[part 12 of 12: packages /ComponentTypes to /VectorAutosarExplorerGeneratedObjects/PDU_GROUP]
AUTOSAR XML (schema 4-3-0)
package /ComponentTypes  (continued)
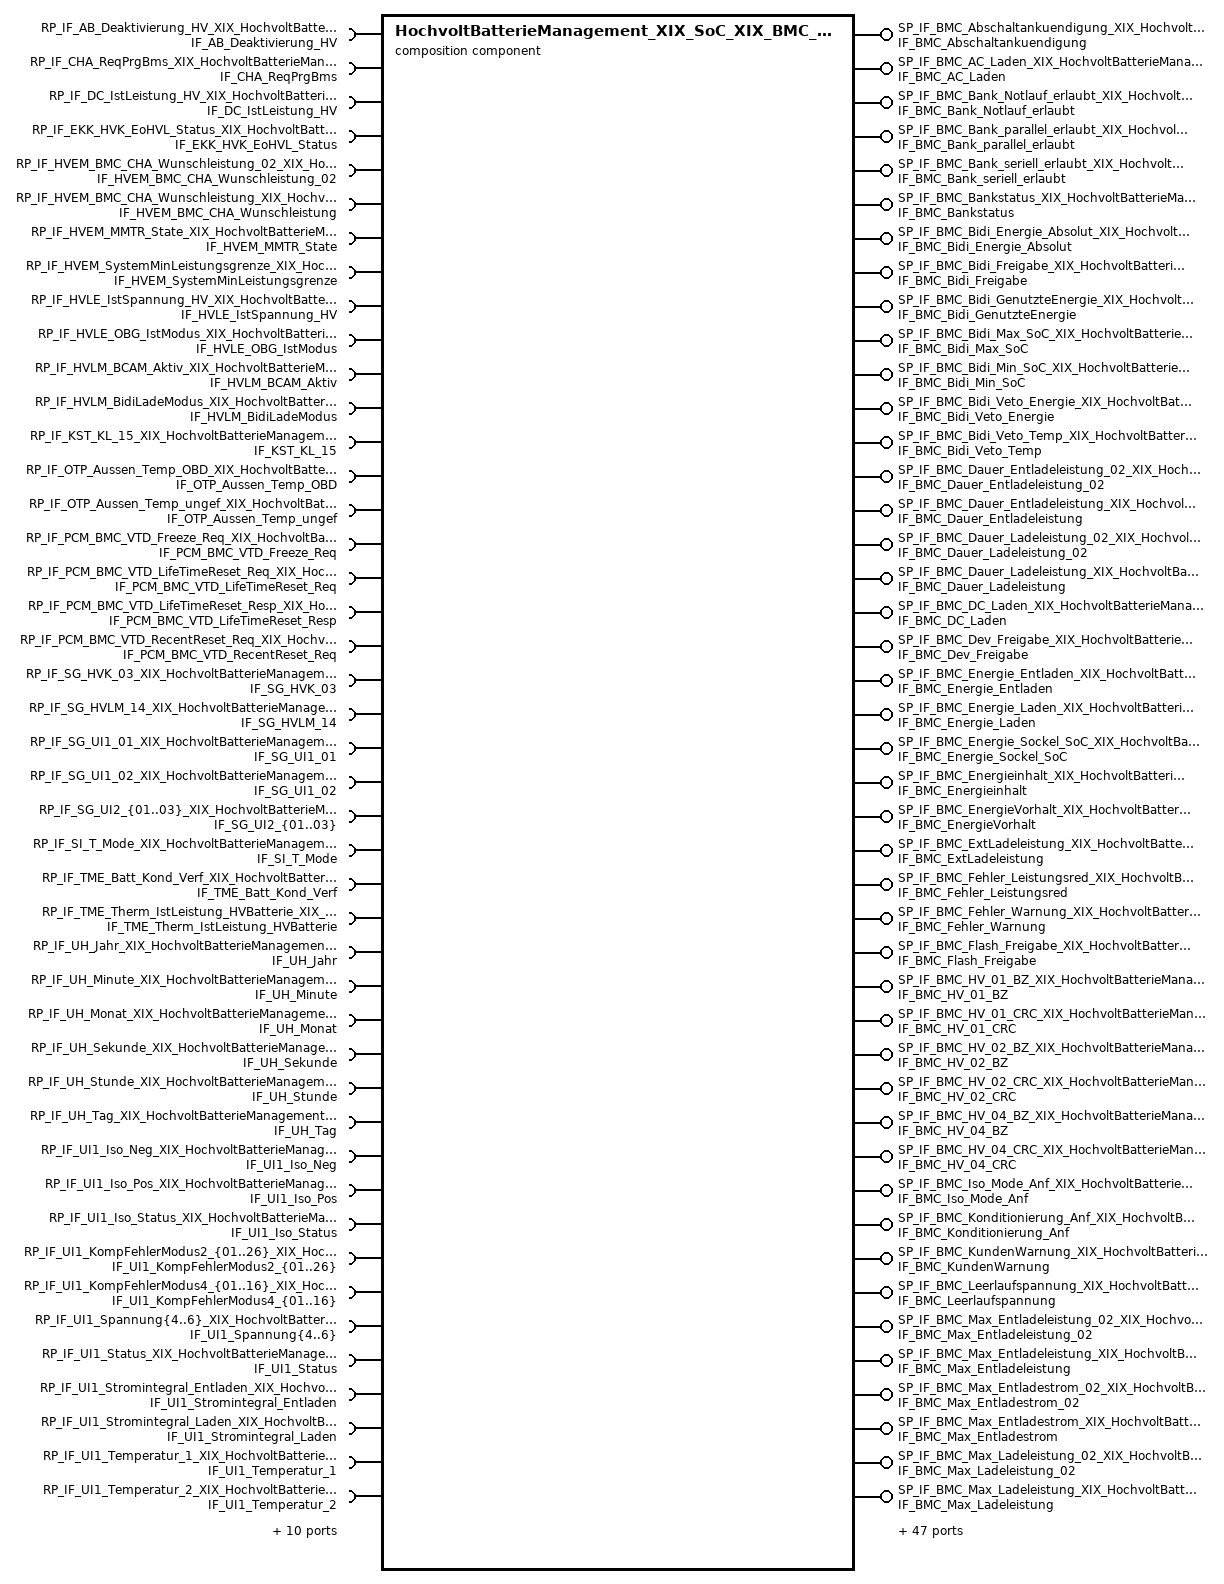
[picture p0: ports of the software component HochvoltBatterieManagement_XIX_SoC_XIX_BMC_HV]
  composition sw component type HochvoltBatterieManagement_XIX_SoC_XIX_BMC_HV
    91 x provide port:
      SP_IF_BMC_Abschaltankuendigung_XIX_HochvoltBatterieManagement_XIX_SoC_XIX_BMC_HV: provided-interface=IF_BMC_Abschaltankuendigung
      SP_IF_BMC_AC_Laden_XIX_HochvoltBatterieManagement_XIX_SoC_XIX_BMC_HV: provided-interface=IF_BMC_AC_Laden
      SP_IF_BMC_Bank_Notlauf_erlaubt_XIX_HochvoltBatterieManagement_XIX_SoC_XIX_BMC_HV: provided-interface=IF_BMC_Bank_Notlauf_erlaubt
      SP_IF_BMC_Bank_parallel_erlaubt_XIX_HochvoltBatterieManagement_XIX_SoC_XIX_BMC_HV: provided-interface=IF_BMC_Bank_parallel_erlaubt
      SP_IF_BMC_Bank_seriell_erlaubt_XIX_HochvoltBatterieManagement_XIX_SoC_XIX_BMC_HV: provided-interface=IF_BMC_Bank_seriell_erlaubt
      SP_IF_BMC_Bankstatus_XIX_HochvoltBatterieManagement_XIX_SoC_XIX_BMC_HV: provided-interface=IF_BMC_Bankstatus
      SP_IF_BMC_Bidi_Energie_Absolut_XIX_HochvoltBatterieManagement_XIX_SoC_XIX_BMC_HV: provided-interface=IF_BMC_Bidi_Energie_Absolut
      SP_IF_BMC_Bidi_Freigabe_XIX_HochvoltBatterieManagement_XIX_SoC_XIX_BMC_HV: provided-interface=IF_BMC_Bidi_Freigabe
      SP_IF_BMC_Bidi_GenutzteEnergie_XIX_HochvoltBatterieManagement_XIX_SoC_XIX_BMC_HV: provided-interface=IF_BMC_Bidi_GenutzteEnergie
      SP_IF_BMC_Bidi_Max_SoC_XIX_HochvoltBatterieManagement_XIX_SoC_XIX_BMC_HV: provided-interface=IF_BMC_Bidi_Max_SoC
      SP_IF_BMC_Bidi_Min_SoC_XIX_HochvoltBatterieManagement_XIX_SoC_XIX_BMC_HV: provided-interface=IF_BMC_Bidi_Min_SoC
      SP_IF_BMC_Bidi_Veto_Energie_XIX_HochvoltBatterieManagement_XIX_SoC_XIX_BMC_HV: provided-interface=IF_BMC_Bidi_Veto_Energie
      SP_IF_BMC_Bidi_Veto_Temp_XIX_HochvoltBatterieManagement_XIX_SoC_XIX_BMC_HV: provided-interface=IF_BMC_Bidi_Veto_Temp
      SP_IF_BMC_Dauer_Entladeleistung_02_XIX_HochvoltBatterieManagement_XIX_SoC_XIX_BMC_HV: provided-interface=IF_BMC_Dauer_Entladeleistung_02
      SP_IF_BMC_Dauer_Entladeleistung_XIX_HochvoltBatterieManagement_XIX_SoC_XIX_BMC_HV: provided-interface=IF_BMC_Dauer_Entladeleistung
      SP_IF_BMC_Dauer_Ladeleistung_02_XIX_HochvoltBatterieManagement_XIX_SoC_XIX_BMC_HV: provided-interface=IF_BMC_Dauer_Ladeleistung_02
      SP_IF_BMC_Dauer_Ladeleistung_XIX_HochvoltBatterieManagement_XIX_SoC_XIX_BMC_HV: provided-interface=IF_BMC_Dauer_Ladeleistung
      SP_IF_BMC_DC_Laden_XIX_HochvoltBatterieManagement_XIX_SoC_XIX_BMC_HV: provided-interface=IF_BMC_DC_Laden
      SP_IF_BMC_Dev_Freigabe_XIX_HochvoltBatterieManagement_XIX_SoC_XIX_BMC_HV: provided-interface=IF_BMC_Dev_Freigabe
      SP_IF_BMC_Energie_Entladen_XIX_HochvoltBatterieManagement_XIX_SoC_XIX_BMC_HV: provided-interface=IF_BMC_Energie_Entladen
      SP_IF_BMC_Energie_Laden_XIX_HochvoltBatterieManagement_XIX_SoC_XIX_BMC_HV: provided-interface=IF_BMC_Energie_Laden
      SP_IF_BMC_Energie_Sockel_SoC_XIX_HochvoltBatterieManagement_XIX_SoC_XIX_BMC_HV: provided-interface=IF_BMC_Energie_Sockel_SoC
      SP_IF_BMC_Energieinhalt_XIX_HochvoltBatterieManagement_XIX_SoC_XIX_BMC_HV: provided-interface=IF_BMC_Energieinhalt
      SP_IF_BMC_EnergieVorhalt_XIX_HochvoltBatterieManagement_XIX_SoC_XIX_BMC_HV: provided-interface=IF_BMC_EnergieVorhalt
      SP_IF_BMC_ExtLadeleistung_XIX_HochvoltBatterieManagement_XIX_SoC_XIX_BMC_HV: provided-interface=IF_BMC_ExtLadeleistung
      SP_IF_BMC_Fehler_Leistungsred_XIX_HochvoltBatterieManagement_XIX_SoC_XIX_BMC_HV: provided-interface=IF_BMC_Fehler_Leistungsred
      SP_IF_BMC_Fehler_Warnung_XIX_HochvoltBatterieManagement_XIX_SoC_XIX_BMC_HV: provided-interface=IF_BMC_Fehler_Warnung
      SP_IF_BMC_Flash_Freigabe_XIX_HochvoltBatterieManagement_XIX_SoC_XIX_BMC_HV: provided-interface=IF_BMC_Flash_Freigabe
      SP_IF_BMC_HV_01_BZ_XIX_HochvoltBatterieManagement_XIX_SoC_XIX_BMC_HV: provided-interface=IF_BMC_HV_01_BZ
      SP_IF_BMC_HV_01_CRC_XIX_HochvoltBatterieManagement_XIX_SoC_XIX_BMC_HV: provided-interface=IF_BMC_HV_01_CRC
      SP_IF_BMC_HV_02_BZ_XIX_HochvoltBatterieManagement_XIX_SoC_XIX_BMC_HV: provided-interface=IF_BMC_HV_02_BZ
      SP_IF_BMC_HV_02_CRC_XIX_HochvoltBatterieManagement_XIX_SoC_XIX_BMC_HV: provided-interface=IF_BMC_HV_02_CRC
      SP_IF_BMC_HV_04_BZ_XIX_HochvoltBatterieManagement_XIX_SoC_XIX_BMC_HV: provided-interface=IF_BMC_HV_04_BZ
      SP_IF_BMC_HV_04_CRC_XIX_HochvoltBatterieManagement_XIX_SoC_XIX_BMC_HV: provided-interface=IF_BMC_HV_04_CRC
      SP_IF_BMC_Iso_Mode_Anf_XIX_HochvoltBatterieManagement_XIX_SoC_XIX_BMC_HV: provided-interface=IF_BMC_Iso_Mode_Anf
      SP_IF_BMC_Konditionierung_Anf_XIX_HochvoltBatterieManagement_XIX_SoC_XIX_BMC_HV: provided-interface=IF_BMC_Konditionierung_Anf
      SP_IF_BMC_KundenWarnung_XIX_HochvoltBatterieManagement_XIX_SoC_XIX_BMC_HV: provided-interface=IF_BMC_KundenWarnung
      SP_IF_BMC_Leerlaufspannung_XIX_HochvoltBatterieManagement_XIX_SoC_XIX_BMC_HV: provided-interface=IF_BMC_Leerlaufspannung
      SP_IF_BMC_Max_Entladeleistung_02_XIX_HochvoltBatterieManagement_XIX_SoC_XIX_BMC_HV: provided-interface=IF_BMC_Max_Entladeleistung_02
      SP_IF_BMC_Max_Entladeleistung_XIX_HochvoltBatterieManagement_XIX_SoC_XIX_BMC_HV: provided-interface=IF_BMC_Max_Entladeleistung
      SP_IF_BMC_Max_Entladestrom_02_XIX_HochvoltBatterieManagement_XIX_SoC_XIX_BMC_HV: provided-interface=IF_BMC_Max_Entladestrom_02
      SP_IF_BMC_Max_Entladestrom_XIX_HochvoltBatterieManagement_XIX_SoC_XIX_BMC_HV: provided-interface=IF_BMC_Max_Entladestrom
      SP_IF_BMC_Max_Ladeleistung_02_XIX_HochvoltBatterieManagement_XIX_SoC_XIX_BMC_HV: provided-interface=IF_BMC_Max_Ladeleistung_02
      SP_IF_BMC_Max_Ladeleistung_XIX_HochvoltBatterieManagement_XIX_SoC_XIX_BMC_HV: provided-interface=IF_BMC_Max_Ladeleistung
      SP_IF_BMC_Max_Ladestrom_02_XIX_HochvoltBatterieManagement_XIX_SoC_XIX_BMC_HV: provided-interface=IF_BMC_Max_Ladestrom_02
      SP_IF_BMC_Max_Ladestrom_XIX_HochvoltBatterieManagement_XIX_SoC_XIX_BMC_HV: provided-interface=IF_BMC_Max_Ladestrom
      SP_IF_BMC_Max_Spannung_XIX_HochvoltBatterieManagement_XIX_SoC_XIX_BMC_HV: provided-interface=IF_BMC_Max_Spannung
      SP_IF_BMC_MaxEnergieinhalt_XIX_HochvoltBatterieManagement_XIX_SoC_XIX_BMC_HV: provided-interface=IF_BMC_MaxEnergieinhalt
      SP_IF_BMC_Min_Spannung_XIX_HochvoltBatterieManagement_XIX_SoC_XIX_BMC_HV: provided-interface=IF_BMC_Min_Spannung
      SP_IF_BMC_MinDyn_Entladespannung_XIX_HochvoltBatterieManagement_XIX_SoC_XIX_BMC_HV: provided-interface=IF_BMC_MinDyn_Entladespannung
      SP_IF_BMC_MinDyn_Ladespannung_XIX_HochvoltBatterieManagement_XIX_SoC_XIX_BMC_HV: provided-interface=IF_BMC_MinDyn_Ladespannung
      SP_IF_BMC_MMTR_Status_XIX_HochvoltBatterieManagement_XIX_SoC_XIX_BMC_HV: provided-interface=IF_BMC_MMTR_Status
      SP_IF_BMC_NutzbareKapazitaet_XIX_HochvoltBatterieManagement_XIX_SoC_XIX_BMC_HV: provided-interface=IF_BMC_NutzbareKapazitaet
      SP_IF_BMC_NutzbarerSOC_XIX_HochvoltBatterieManagement_XIX_SoC_XIX_BMC_HV: provided-interface=IF_BMC_NutzbarerSOC
      SP_IF_BMC_PCM_VTD_Freeze_Req_XIX_HochvoltBatterieManagement_XIX_SoC_XIX_BMC_HV: provided-interface=IF_BMC_PCM_VTD_Freeze_Req
      SP_IF_BMC_PCM_VTD_LifeTimeReset_Req_XIX_HochvoltBatterieManagement_XIX_SoC_XIX_BMC_HV: provided-interface=IF_BMC_PCM_VTD_LifeTimeReset_Req
      SP_IF_BMC_PCM_VTD_LifeTimeReset_Resp_XIX_HochvoltBatterieManagement_XIX_SoC_XIX_BMC_HV: provided-interface=IF_BMC_PCM_VTD_LifeTimeReset_Resp
      SP_IF_BMC_PCM_VTD_RecentReset_Req_XIX_HochvoltBatterieManagement_XIX_SoC_XIX_BMC_HV: provided-interface=IF_BMC_PCM_VTD_RecentReset_Req
      SP_IF_BMC_PerfInd_Entladen_XIX_HochvoltBatterieManagement_XIX_SoC_XIX_BMC_HV: provided-interface=IF_BMC_PerfInd_Entladen
      SP_IF_BMC_PerfInd_Laden_XIX_HochvoltBatterieManagement_XIX_SoC_XIX_BMC_HV: provided-interface=IF_BMC_PerfInd_Laden
      SP_IF_BMC_PredLeistung_StuetzungNV_XIX_HochvoltBatterieManagement_XIX_SoC_XIX_BMC_HV: provided-interface=IF_BMC_PredLeistung_StuetzungNV
      SP_IF_BMC_Range_Indikator_XIX_HochvoltBatterieManagement_XIX_SoC_XIX_BMC_HV: provided-interface=IF_BMC_Range_Indikator
      SP_IF_BMC_Rekuperation_Ueberlauf_XIX_HochvoltBatterieManagement_XIX_SoC_XIX_BMC_HV: provided-interface=IF_BMC_Rekuperation_Ueberlauf
      SP_IF_BMC_Rekuperation_XIX_HochvoltBatterieManagement_XIX_SoC_XIX_BMC_HV: provided-interface=IF_BMC_Rekuperation
      SP_IF_BMC_RuecklaufTemperatur_XIX_HochvoltBatterieManagement_XIX_SoC_XIX_BMC_HV: provided-interface=IF_BMC_RuecklaufTemperatur
      SP_IF_BMC_Spannung_DC_Ladesaeule_XIX_HochvoltBatterieManagement_XIX_SoC_XIX_BMC_HV: provided-interface=IF_BMC_Spannung_DC_Ladesaeule
      SP_IF_BMC_Spannung_XIX_HochvoltBatterieManagement_XIX_SoC_XIX_BMC_HV: provided-interface=IF_BMC_Spannung
      SP_IF_BMC_Spannung_ZwischenKreis_2_XIX_HochvoltBatterieManagement_XIX_SoC_XIX_BMC_HV: provided-interface=IF_BMC_Spannung_ZwischenKreis_2
      SP_IF_BMC_Spannung_ZwischenKreis_XIX_HochvoltBatterieManagement_XIX_SoC_XIX_BMC_HV: provided-interface=IF_BMC_Spannung_ZwischenKreis
      SP_IF_BMC_Status_DCLS_XIX_HochvoltBatterieManagement_XIX_SoC_XIX_BMC_HV: provided-interface=IF_BMC_Status_DCLS
      SP_IF_BMC_Strom_02_XIX_HochvoltBatterieManagement_XIX_SoC_XIX_BMC_HV: provided-interface=IF_BMC_Strom_02
      SP_IF_BMC_Strom_XIX_HochvoltBatterieManagement_XIX_SoC_XIX_BMC_HV: provided-interface=IF_BMC_Strom
      SP_IF_BMC_TechnischerSOC_XIX_HochvoltBatterieManagement_XIX_SoC_XIX_BMC_HV: provided-interface=IF_BMC_TechnischerSOC
      SP_IF_BMC_Temperatur_XIX_HochvoltBatterieManagement_XIX_SoC_XIX_BMC_HV: provided-interface=IF_BMC_Temperatur
      SP_IF_BMC_ThermAuslastung_XIX_HochvoltBatterieManagement_XIX_SoC_XIX_BMC_HV: provided-interface=IF_BMC_ThermAuslastung
      SP_IF_BMC_ThermSpreizung_XIX_HochvoltBatterieManagement_XIX_SoC_XIX_BMC_HV: provided-interface=IF_BMC_ThermSpreizung
      SP_IF_BMC_UBE_Indik_last_update_km_XIX_HochvoltBatterieManagement_XIX_SoC_XIX_BMC_HV: provided-interface=IF_BMC_UBE_Indik_last_update_km
      SP_IF_BMC_UBE_Indikator_XIX_HochvoltBatterieManagement_XIX_SoC_XIX_BMC_HV: provided-interface=IF_BMC_UBE_Indikator
      SP_IF_BMC_UI1_Spannung1_Schalt_Anf_XIX_HochvoltBatterieManagement_XIX_SoC_XIX_BMC_HV: provided-interface=IF_BMC_UI1_Spannung1_Schalt_Anf
      SP_IF_BMC_UI1_Spannung2_Schalt_Anf_XIX_HochvoltBatterieManagement_XIX_SoC_XIX_BMC_HV: provided-interface=IF_BMC_UI1_Spannung2_Schalt_Anf
      SP_IF_BMC_UI2_Spannung1_Schalt_Anf_XIX_HochvoltBatterieManagement_XIX_SoC_XIX_BMC_HV: provided-interface=IF_BMC_UI2_Spannung1_Schalt_Anf
      SP_IF_BMC_UI2_Spannung2_Schalt_Anf_XIX_HochvoltBatterieManagement_XIX_SoC_XIX_BMC_HV: provided-interface=IF_BMC_UI2_Spannung2_Schalt_Anf
      SP_IF_BMC_Unterboden_Warnung_XIX_HochvoltBatterieManagement_XIX_SoC_XIX_BMC_HV: provided-interface=IF_BMC_Unterboden_Warnung
      SP_IF_BMC_Verbauinfo_ACSchuetz_XIX_HochvoltBatterieManagement_XIX_SoC_XIX_BMC_HV: provided-interface=IF_BMC_Verbauinfo_ACSchuetz
      SP_IF_BMC_Verbauinfo_Bank_XIX_HochvoltBatterieManagement_XIX_SoC_XIX_BMC_HV: provided-interface=IF_BMC_Verbauinfo_Bank
      SP_IF_BMC_Verbrauch_Ueberlauf_XIX_HochvoltBatterieManagement_XIX_SoC_XIX_BMC_HV: provided-interface=IF_BMC_Verbrauch_Ueberlauf
      SP_IF_BMC_Verbrauch_XIX_HochvoltBatterieManagement_XIX_SoC_XIX_BMC_HV: provided-interface=IF_BMC_Verbrauch
      SP_IF_BMC_VerlustEnergie_XIX_HochvoltBatterieManagement_XIX_SoC_XIX_BMC_HV: provided-interface=IF_BMC_VerlustEnergie
      SP_IF_BMC_VorlaufTemperatur_XIX_HochvoltBatterieManagement_XIX_SoC_XIX_BMC_HV: provided-interface=IF_BMC_VorlaufTemperatur
      SP_IF_BMC_ZellTemp_virtuell_max_XIX_HochvoltBatterieManagement_XIX_SoC_XIX_BMC_HV: provided-interface=IF_BMC_ZellTemp_virtuell_max
      SP_IF_BMC_ZellTemp_virtuell_min_XIX_HochvoltBatterieManagement_XIX_SoC_XIX_BMC_HV: provided-interface=IF_BMC_ZellTemp_virtuell_min
    138 x require port:
      RP_IF_AB_Deaktivierung_HV_XIX_HochvoltBatterieManagement_XIX_SoC_XIX_BMC_HV: required-interface=IF_AB_Deaktivierung_HV
      RP_IF_CHA_ReqPrgBms_XIX_HochvoltBatterieManagement_XIX_SoC_XIX_BMC_HV: required-interface=IF_CHA_ReqPrgBms
      RP_IF_DC_IstLeistung_HV_XIX_HochvoltBatterieManagement_XIX_SoC_XIX_BMC_HV: required-interface=IF_DC_IstLeistung_HV
      RP_IF_EKK_HVK_EoHVL_Status_XIX_HochvoltBatterieManagement_XIX_SoC_XIX_BMC_HV: required-interface=IF_EKK_HVK_EoHVL_Status
      RP_IF_HVEM_BMC_CHA_Wunschleistung_02_XIX_HochvoltBatterieManagement_XIX_SoC_XIX_BMC_HV: required-interface=IF_HVEM_BMC_CHA_Wunschleistung_02
      RP_IF_HVEM_BMC_CHA_Wunschleistung_XIX_HochvoltBatterieManagement_XIX_SoC_XIX_BMC_HV: required-interface=IF_HVEM_BMC_CHA_Wunschleistung
      RP_IF_HVEM_MMTR_State_XIX_HochvoltBatterieManagement_XIX_SoC_XIX_BMC_HV: required-interface=IF_HVEM_MMTR_State
      RP_IF_HVEM_SystemMinLeistungsgrenze_XIX_HochvoltBatterieManagement_XIX_SoC_XIX_BMC_HV: required-interface=IF_HVEM_SystemMinLeistungsgrenze
      RP_IF_HVLE_IstSpannung_HV_XIX_HochvoltBatterieManagement_XIX_SoC_XIX_BMC_HV: required-interface=IF_HVLE_IstSpannung_HV
      RP_IF_HVLE_OBG_IstModus_XIX_HochvoltBatterieManagement_XIX_SoC_XIX_BMC_HV: required-interface=IF_HVLE_OBG_IstModus
      RP_IF_HVLM_BCAM_Aktiv_XIX_HochvoltBatterieManagement_XIX_SoC_XIX_BMC_HV: required-interface=IF_HVLM_BCAM_Aktiv
      RP_IF_HVLM_BidiLadeModus_XIX_HochvoltBatterieManagement_XIX_SoC_XIX_BMC_HV: required-interface=IF_HVLM_BidiLadeModus
      RP_IF_KST_KL_15_XIX_HochvoltBatterieManagement_XIX_SoC_XIX_BMC_HV: required-interface=IF_KST_KL_15
      RP_IF_OTP_Aussen_Temp_OBD_XIX_HochvoltBatterieManagement_XIX_SoC_XIX_BMC_HV: required-interface=IF_OTP_Aussen_Temp_OBD
      RP_IF_OTP_Aussen_Temp_ungef_XIX_HochvoltBatterieManagement_XIX_SoC_XIX_BMC_HV: required-interface=IF_OTP_Aussen_Temp_ungef
      RP_IF_PCM_BMC_VTD_Freeze_Req_XIX_HochvoltBatterieManagement_XIX_SoC_XIX_BMC_HV: required-interface=IF_PCM_BMC_VTD_Freeze_Req
      RP_IF_PCM_BMC_VTD_LifeTimeReset_Req_XIX_HochvoltBatterieManagement_XIX_SoC_XIX_BMC_HV: required-interface=IF_PCM_BMC_VTD_LifeTimeReset_Req
      RP_IF_PCM_BMC_VTD_LifeTimeReset_Resp_XIX_HochvoltBatterieManagement_XIX_SoC_XIX_BMC_HV: required-interface=IF_PCM_BMC_VTD_LifeTimeReset_Resp
      RP_IF_PCM_BMC_VTD_RecentReset_Req_XIX_HochvoltBatterieManagement_XIX_SoC_XIX_BMC_HV: required-interface=IF_PCM_BMC_VTD_RecentReset_Req
      RP_IF_SG_HVK_03_XIX_HochvoltBatterieManagement_XIX_SoC_XIX_BMC_HV: required-interface=IF_SG_HVK_03
      RP_IF_SG_HVLM_14_XIX_HochvoltBatterieManagement_XIX_SoC_XIX_BMC_HV: required-interface=IF_SG_HVLM_14
      RP_IF_SG_UI1_01_XIX_HochvoltBatterieManagement_XIX_SoC_XIX_BMC_HV: required-interface=IF_SG_UI1_01
      RP_IF_SG_UI1_02_XIX_HochvoltBatterieManagement_XIX_SoC_XIX_BMC_HV: required-interface=IF_SG_UI1_02
      RP_IF_SG_UI2_{01..03}_XIX_HochvoltBatterieManagement_XIX_SoC_XIX_BMC_HV: required-interface=IF_SG_UI2_{01..03}
      RP_IF_SI_T_Mode_XIX_HochvoltBatterieManagement_XIX_SoC_XIX_BMC_HV: required-interface=IF_SI_T_Mode
      RP_IF_TME_Batt_Kond_Verf_XIX_HochvoltBatterieManagement_XIX_SoC_XIX_BMC_HV: required-interface=IF_TME_Batt_Kond_Verf
      RP_IF_TME_Therm_IstLeistung_HVBatterie_XIX_HochvoltBatterieManagement_XIX_SoC_XIX_BMC_HV: required-interface=IF_TME_Therm_IstLeistung_HVBatterie
      RP_IF_UH_Jahr_XIX_HochvoltBatterieManagement_XIX_SoC_XIX_BMC_HV: required-interface=IF_UH_Jahr
      RP_IF_UH_Minute_XIX_HochvoltBatterieManagement_XIX_SoC_XIX_BMC_HV: required-interface=IF_UH_Minute
      RP_IF_UH_Monat_XIX_HochvoltBatterieManagement_XIX_SoC_XIX_BMC_HV: required-interface=IF_UH_Monat
      RP_IF_UH_Sekunde_XIX_HochvoltBatterieManagement_XIX_SoC_XIX_BMC_HV: required-interface=IF_UH_Sekunde
      RP_IF_UH_Stunde_XIX_HochvoltBatterieManagement_XIX_SoC_XIX_BMC_HV: required-interface=IF_UH_Stunde
      RP_IF_UH_Tag_XIX_HochvoltBatterieManagement_XIX_SoC_XIX_BMC_HV: required-interface=IF_UH_Tag
      RP_IF_UI1_Iso_Neg_XIX_HochvoltBatterieManagement_XIX_SoC_XIX_BMC_HV: required-interface=IF_UI1_Iso_Neg
      RP_IF_UI1_Iso_Pos_XIX_HochvoltBatterieManagement_XIX_SoC_XIX_BMC_HV: required-interface=IF_UI1_Iso_Pos
      RP_IF_UI1_Iso_Status_XIX_HochvoltBatterieManagement_XIX_SoC_XIX_BMC_HV: required-interface=IF_UI1_Iso_Status
      RP_IF_UI1_KompFehlerModus2_{01..26}_XIX_HochvoltBatterieManagement_XIX_SoC_XIX_BMC_HV: required-interface=IF_UI1_KompFehlerModus2_{01..26}
      RP_IF_UI1_KompFehlerModus4_{01..16}_XIX_HochvoltBatterieManagement_XIX_SoC_XIX_BMC_HV: required-interface=IF_UI1_KompFehlerModus4_{01..16}
      RP_IF_UI1_Spannung{4..6}_XIX_HochvoltBatterieManagement_XIX_SoC_XIX_BMC_HV: required-interface=IF_UI1_Spannung{4..6}
      RP_IF_UI1_Status_XIX_HochvoltBatterieManagement_XIX_SoC_XIX_BMC_HV: required-interface=IF_UI1_Status
      RP_IF_UI1_Stromintegral_Entladen_XIX_HochvoltBatterieManagement_XIX_SoC_XIX_BMC_HV: required-interface=IF_UI1_Stromintegral_Entladen
      RP_IF_UI1_Stromintegral_Laden_XIX_HochvoltBatterieManagement_XIX_SoC_XIX_BMC_HV: required-interface=IF_UI1_Stromintegral_Laden
      RP_IF_UI1_Temperatur_1_XIX_HochvoltBatterieManagement_XIX_SoC_XIX_BMC_HV: required-interface=IF_UI1_Temperatur_1
      RP_IF_UI1_Temperatur_2_XIX_HochvoltBatterieManagement_XIX_SoC_XIX_BMC_HV: required-interface=IF_UI1_Temperatur_2
      RP_IF_UI2_KompFehlerModus2_{01..26}_XIX_HochvoltBatterieManagement_XIX_SoC_XIX_BMC_HV: required-interface=IF_UI2_KompFehlerModus2_{01..26}
      RP_IF_UI2_KompFehlerModus4_{01..16}_XIX_HochvoltBatterieManagement_XIX_SoC_XIX_BMC_HV: required-interface=IF_UI2_KompFehlerModus4_{01..16}
      RP_IF_UI2_Status_XIX_HochvoltBatterieManagement_XIX_SoC_XIX_BMC_HV: required-interface=IF_UI2_Status
      RP_IF_UI2_Stromintegral_Entladen_XIX_HochvoltBatterieManagement_XIX_SoC_XIX_BMC_HV: required-interface=IF_UI2_Stromintegral_Entladen
      RP_IF_UI2_Stromintegral_Laden_XIX_HochvoltBatterieManagement_XIX_SoC_XIX_BMC_HV: required-interface=IF_UI2_Stromintegral_Laden
      RP_IF_UI2_Temperatur_1_XIX_HochvoltBatterieManagement_XIX_SoC_XIX_BMC_HV: required-interface=IF_UI2_Temperatur_1
      RP_IF_UI2_Temperatur_2_XIX_HochvoltBatterieManagement_XIX_SoC_XIX_BMC_HV: required-interface=IF_UI2_Temperatur_2
      RP_IF_ZM_HV_Auszeit_HiRes_XIX_HochvoltBatterieManagement_XIX_SoC_XIX_BMC_HV: required-interface=IF_ZM_HV_Auszeit_HiRes
      RP_IF_ZM_HV_Auszeit_Status_XIX_HochvoltBatterieManagement_XIX_SoC_XIX_BMC_HV: required-interface=IF_ZM_HV_Auszeit_Status
      RP_IF_ZM_HV_Auszeit_XIX_HochvoltBatterieManagement_XIX_SoC_XIX_BMC_HV: required-interface=IF_ZM_HV_Auszeit
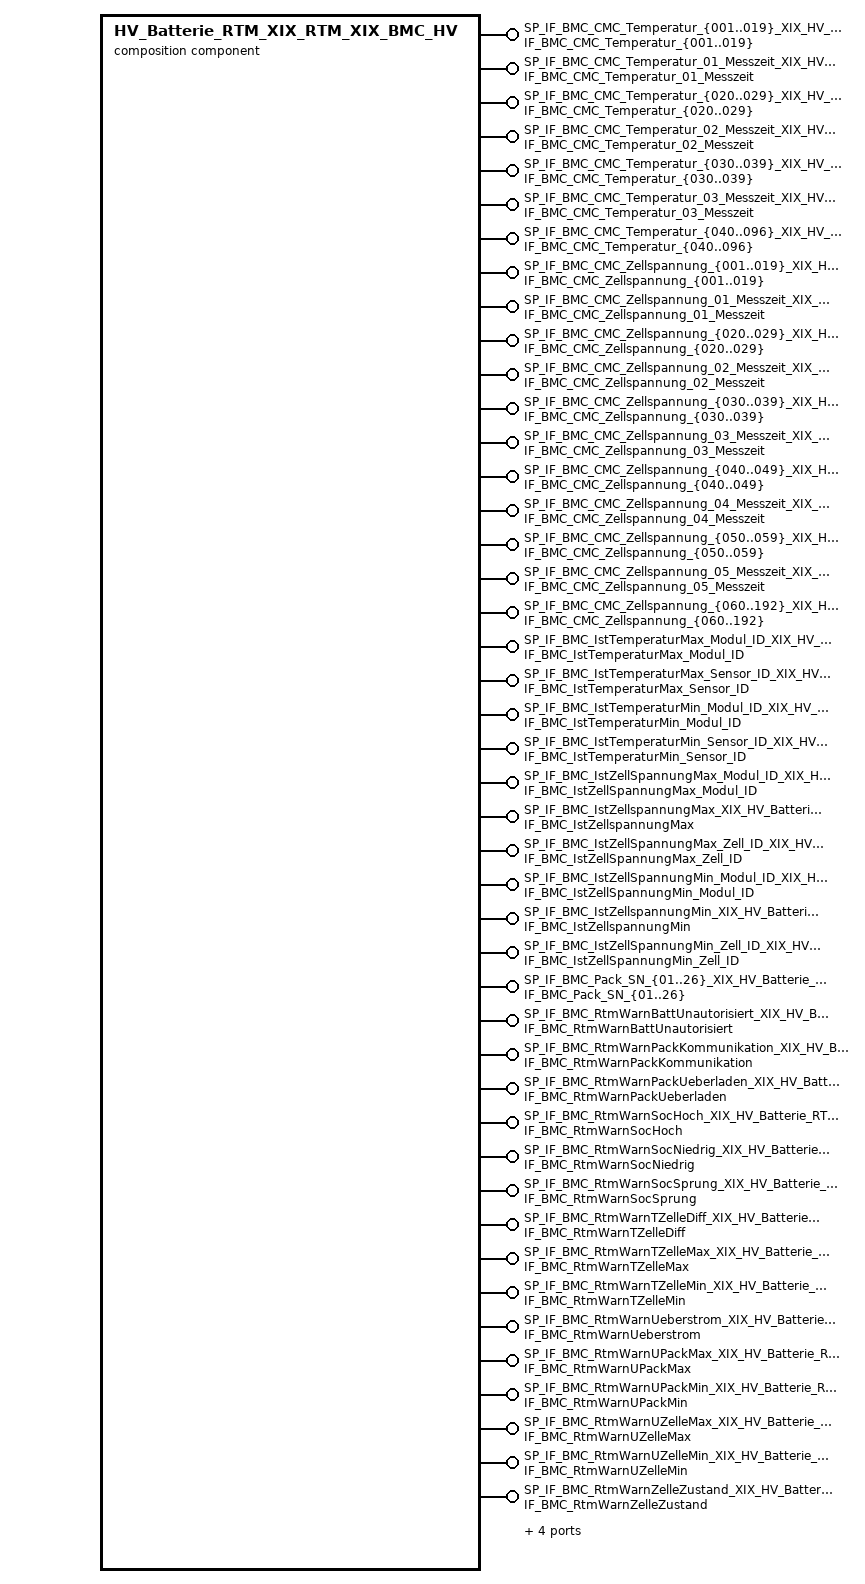
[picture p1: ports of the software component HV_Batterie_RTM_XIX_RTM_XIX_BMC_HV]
  composition sw component type HV_Batterie_RTM_XIX_RTM_XIX_BMC_HV
    351 x provide port:
      SP_IF_BMC_CMC_Temperatur_{001..019}_XIX_HV_Batterie_RTM_XIX_RTM_XIX_BMC_HV: provided-interface=IF_BMC_CMC_Temperatur_{001..019}
      SP_IF_BMC_CMC_Temperatur_01_Messzeit_XIX_HV_Batterie_RTM_XIX_RTM_XIX_BMC_HV: provided-interface=IF_BMC_CMC_Temperatur_01_Messzeit
      SP_IF_BMC_CMC_Temperatur_{020..029}_XIX_HV_Batterie_RTM_XIX_RTM_XIX_BMC_HV: provided-interface=IF_BMC_CMC_Temperatur_{020..029}
      SP_IF_BMC_CMC_Temperatur_02_Messzeit_XIX_HV_Batterie_RTM_XIX_RTM_XIX_BMC_HV: provided-interface=IF_BMC_CMC_Temperatur_02_Messzeit
      SP_IF_BMC_CMC_Temperatur_{030..039}_XIX_HV_Batterie_RTM_XIX_RTM_XIX_BMC_HV: provided-interface=IF_BMC_CMC_Temperatur_{030..039}
      SP_IF_BMC_CMC_Temperatur_03_Messzeit_XIX_HV_Batterie_RTM_XIX_RTM_XIX_BMC_HV: provided-interface=IF_BMC_CMC_Temperatur_03_Messzeit
      SP_IF_BMC_CMC_Temperatur_{040..096}_XIX_HV_Batterie_RTM_XIX_RTM_XIX_BMC_HV: provided-interface=IF_BMC_CMC_Temperatur_{040..096}
      SP_IF_BMC_CMC_Zellspannung_{001..019}_XIX_HV_Batterie_RTM_XIX_RTM_XIX_BMC_HV: provided-interface=IF_BMC_CMC_Zellspannung_{001..019}
      SP_IF_BMC_CMC_Zellspannung_01_Messzeit_XIX_HV_Batterie_RTM_XIX_RTM_XIX_BMC_HV: provided-interface=IF_BMC_CMC_Zellspannung_01_Messzeit
      SP_IF_BMC_CMC_Zellspannung_{020..029}_XIX_HV_Batterie_RTM_XIX_RTM_XIX_BMC_HV: provided-interface=IF_BMC_CMC_Zellspannung_{020..029}
      SP_IF_BMC_CMC_Zellspannung_02_Messzeit_XIX_HV_Batterie_RTM_XIX_RTM_XIX_BMC_HV: provided-interface=IF_BMC_CMC_Zellspannung_02_Messzeit
      SP_IF_BMC_CMC_Zellspannung_{030..039}_XIX_HV_Batterie_RTM_XIX_RTM_XIX_BMC_HV: provided-interface=IF_BMC_CMC_Zellspannung_{030..039}
      SP_IF_BMC_CMC_Zellspannung_03_Messzeit_XIX_HV_Batterie_RTM_XIX_RTM_XIX_BMC_HV: provided-interface=IF_BMC_CMC_Zellspannung_03_Messzeit
      SP_IF_BMC_CMC_Zellspannung_{040..049}_XIX_HV_Batterie_RTM_XIX_RTM_XIX_BMC_HV: provided-interface=IF_BMC_CMC_Zellspannung_{040..049}
      SP_IF_BMC_CMC_Zellspannung_04_Messzeit_XIX_HV_Batterie_RTM_XIX_RTM_XIX_BMC_HV: provided-interface=IF_BMC_CMC_Zellspannung_04_Messzeit
      SP_IF_BMC_CMC_Zellspannung_{050..059}_XIX_HV_Batterie_RTM_XIX_RTM_XIX_BMC_HV: provided-interface=IF_BMC_CMC_Zellspannung_{050..059}
      SP_IF_BMC_CMC_Zellspannung_05_Messzeit_XIX_HV_Batterie_RTM_XIX_RTM_XIX_BMC_HV: provided-interface=IF_BMC_CMC_Zellspannung_05_Messzeit
      SP_IF_BMC_CMC_Zellspannung_{060..192}_XIX_HV_Batterie_RTM_XIX_RTM_XIX_BMC_HV: provided-interface=IF_BMC_CMC_Zellspannung_{060..192}
      SP_IF_BMC_IstTemperaturMax_Modul_ID_XIX_HV_Batterie_RTM_XIX_RTM_XIX_BMC_HV: provided-interface=IF_BMC_IstTemperaturMax_Modul_ID
      SP_IF_BMC_IstTemperaturMax_Sensor_ID_XIX_HV_Batterie_RTM_XIX_RTM_XIX_BMC_HV: provided-interface=IF_BMC_IstTemperaturMax_Sensor_ID
      SP_IF_BMC_IstTemperaturMin_Modul_ID_XIX_HV_Batterie_RTM_XIX_RTM_XIX_BMC_HV: provided-interface=IF_BMC_IstTemperaturMin_Modul_ID
      SP_IF_BMC_IstTemperaturMin_Sensor_ID_XIX_HV_Batterie_RTM_XIX_RTM_XIX_BMC_HV: provided-interface=IF_BMC_IstTemperaturMin_Sensor_ID
      SP_IF_BMC_IstZellSpannungMax_Modul_ID_XIX_HV_Batterie_RTM_XIX_RTM_XIX_BMC_HV: provided-interface=IF_BMC_IstZellSpannungMax_Modul_ID
      SP_IF_BMC_IstZellspannungMax_XIX_HV_Batterie_RTM_XIX_RTM_XIX_BMC_HV: provided-interface=IF_BMC_IstZellspannungMax
      SP_IF_BMC_IstZellSpannungMax_Zell_ID_XIX_HV_Batterie_RTM_XIX_RTM_XIX_BMC_HV: provided-interface=IF_BMC_IstZellSpannungMax_Zell_ID
      SP_IF_BMC_IstZellSpannungMin_Modul_ID_XIX_HV_Batterie_RTM_XIX_RTM_XIX_BMC_HV: provided-interface=IF_BMC_IstZellSpannungMin_Modul_ID
      SP_IF_BMC_IstZellspannungMin_XIX_HV_Batterie_RTM_XIX_RTM_XIX_BMC_HV: provided-interface=IF_BMC_IstZellspannungMin
      SP_IF_BMC_IstZellSpannungMin_Zell_ID_XIX_HV_Batterie_RTM_XIX_RTM_XIX_BMC_HV: provided-interface=IF_BMC_IstZellSpannungMin_Zell_ID
      SP_IF_BMC_Pack_SN_{01..26}_XIX_HV_Batterie_RTM_XIX_RTM_XIX_BMC_HV: provided-interface=IF_BMC_Pack_SN_{01..26}
      SP_IF_BMC_RtmWarnBattUnautorisiert_XIX_HV_Batterie_RTM_XIX_RTM_XIX_BMC_HV: provided-interface=IF_BMC_RtmWarnBattUnautorisiert
      SP_IF_BMC_RtmWarnPackKommunikation_XIX_HV_Batterie_RTM_XIX_RTM_XIX_BMC_HV: provided-interface=IF_BMC_RtmWarnPackKommunikation
      SP_IF_BMC_RtmWarnPackUeberladen_XIX_HV_Batterie_RTM_XIX_RTM_XIX_BMC_HV: provided-interface=IF_BMC_RtmWarnPackUeberladen
      SP_IF_BMC_RtmWarnSocHoch_XIX_HV_Batterie_RTM_XIX_RTM_XIX_BMC_HV: provided-interface=IF_BMC_RtmWarnSocHoch
      SP_IF_BMC_RtmWarnSocNiedrig_XIX_HV_Batterie_RTM_XIX_RTM_XIX_BMC_HV: provided-interface=IF_BMC_RtmWarnSocNiedrig
      SP_IF_BMC_RtmWarnSocSprung_XIX_HV_Batterie_RTM_XIX_RTM_XIX_BMC_HV: provided-interface=IF_BMC_RtmWarnSocSprung
      SP_IF_BMC_RtmWarnTZelleDiff_XIX_HV_Batterie_RTM_XIX_RTM_XIX_BMC_HV: provided-interface=IF_BMC_RtmWarnTZelleDiff
      SP_IF_BMC_RtmWarnTZelleMax_XIX_HV_Batterie_RTM_XIX_RTM_XIX_BMC_HV: provided-interface=IF_BMC_RtmWarnTZelleMax
      SP_IF_BMC_RtmWarnTZelleMin_XIX_HV_Batterie_RTM_XIX_RTM_XIX_BMC_HV: provided-interface=IF_BMC_RtmWarnTZelleMin
      SP_IF_BMC_RtmWarnUeberstrom_XIX_HV_Batterie_RTM_XIX_RTM_XIX_BMC_HV: provided-interface=IF_BMC_RtmWarnUeberstrom
      SP_IF_BMC_RtmWarnUPackMax_XIX_HV_Batterie_RTM_XIX_RTM_XIX_BMC_HV: provided-interface=IF_BMC_RtmWarnUPackMax
      SP_IF_BMC_RtmWarnUPackMin_XIX_HV_Batterie_RTM_XIX_RTM_XIX_BMC_HV: provided-interface=IF_BMC_RtmWarnUPackMin
      SP_IF_BMC_RtmWarnUZelleMax_XIX_HV_Batterie_RTM_XIX_RTM_XIX_BMC_HV: provided-interface=IF_BMC_RtmWarnUZelleMax
      SP_IF_BMC_RtmWarnUZelleMin_XIX_HV_Batterie_RTM_XIX_RTM_XIX_BMC_HV: provided-interface=IF_BMC_RtmWarnUZelleMin
      SP_IF_BMC_RtmWarnZelleZustand_XIX_HV_Batterie_RTM_XIX_RTM_XIX_BMC_HV: provided-interface=IF_BMC_RtmWarnZelleZustand
      SP_IF_BMC_Spannung_Messzeit_XIX_HV_Batterie_RTM_XIX_RTM_XIX_BMC_HV: provided-interface=IF_BMC_Spannung_Messzeit
      SP_IF_BMC_Strom_Messzeit_XIX_HV_Batterie_RTM_XIX_RTM_XIX_BMC_HV: provided-interface=IF_BMC_Strom_Messzeit
      SP_IF_BMC_Temperatur_hoechste_XIX_HV_Batterie_RTM_XIX_RTM_XIX_BMC_HV: provided-interface=IF_BMC_Temperatur_hoechste
      SP_IF_BMC_Temperatur_niedrigste_XIX_HV_Batterie_RTM_XIX_RTM_XIX_BMC_HV: provided-interface=IF_BMC_Temperatur_niedrigste
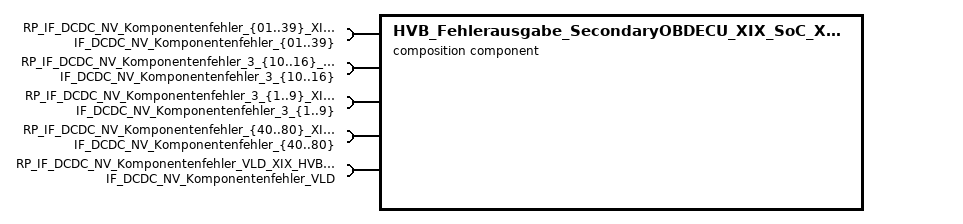
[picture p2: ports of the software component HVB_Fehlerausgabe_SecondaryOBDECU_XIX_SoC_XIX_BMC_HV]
  composition sw component type HVB_Fehlerausgabe_SecondaryOBDECU_XIX_SoC_XIX_BMC_HV
    97 x require port:
      RP_IF_DCDC_NV_Komponentenfehler_{01..39}_XIX_HVB_Fehlerausgabe_SecondaryOBDECU_XIX_SoC_XIX_BMC_HV: required-interface=IF_DCDC_NV_Komponentenfehler_{01..39}
      RP_IF_DCDC_NV_Komponentenfehler_3_{10..16}_XIX_HVB_Fehlerausgabe_SecondaryOBDECU_XIX_SoC_XIX_BMC_HV: required-interface=IF_DCDC_NV_Komponentenfehler_3_{10..16}
      RP_IF_DCDC_NV_Komponentenfehler_3_{1..9}_XIX_HVB_Fehlerausgabe_SecondaryOBDECU_XIX_SoC_XIX_BMC_HV: required-interface=IF_DCDC_NV_Komponentenfehler_3_{1..9}
      RP_IF_DCDC_NV_Komponentenfehler_{40..80}_XIX_HVB_Fehlerausgabe_SecondaryOBDECU_XIX_SoC_XIX_BMC_HV: required-interface=IF_DCDC_NV_Komponentenfehler_{40..80}
      RP_IF_DCDC_NV_Komponentenfehler_VLD_XIX_HVB_Fehlerausgabe_SecondaryOBDECU_XIX_SoC_XIX_BMC_HV: required-interface=IF_DCDC_NV_Komponentenfehler_VLD
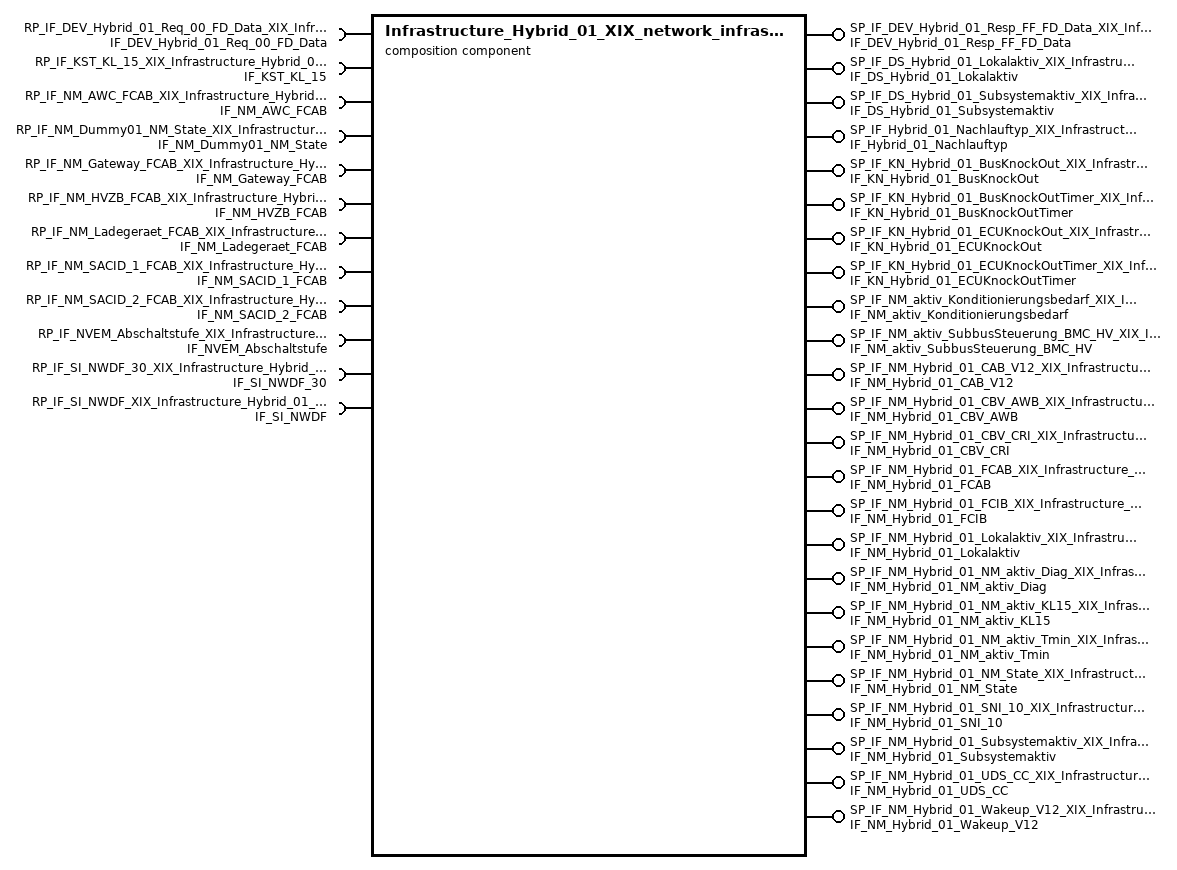
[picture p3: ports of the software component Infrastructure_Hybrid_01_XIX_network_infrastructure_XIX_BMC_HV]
  composition sw component type Infrastructure_Hybrid_01_XIX_network_infrastructure_XIX_BMC_HV
    24 x provide port:
      SP_IF_DEV_Hybrid_01_Resp_FF_FD_Data_XIX_Infrastructure_Hybrid_01_XIX_network_infrastructure_XIX_BMC_HV: provided-interface=IF_DEV_Hybrid_01_Resp_FF_FD_Data
      SP_IF_DS_Hybrid_01_Lokalaktiv_XIX_Infrastructure_Hybrid_01_XIX_network_infrastructure_XIX_BMC_HV: provided-interface=IF_DS_Hybrid_01_Lokalaktiv
      SP_IF_DS_Hybrid_01_Subsystemaktiv_XIX_Infrastructure_Hybrid_01_XIX_network_infrastructure_XIX_BMC_HV: provided-interface=IF_DS_Hybrid_01_Subsystemaktiv
      SP_IF_Hybrid_01_Nachlauftyp_XIX_Infrastructure_Hybrid_01_XIX_network_infrastructure_XIX_BMC_HV: provided-interface=IF_Hybrid_01_Nachlauftyp
      SP_IF_KN_Hybrid_01_BusKnockOut_XIX_Infrastructure_Hybrid_01_XIX_network_infrastructure_XIX_BMC_HV: provided-interface=IF_KN_Hybrid_01_BusKnockOut
      SP_IF_KN_Hybrid_01_BusKnockOutTimer_XIX_Infrastructure_Hybrid_01_XIX_network_infrastructure_XIX_BMC_HV: provided-interface=IF_KN_Hybrid_01_BusKnockOutTimer
      SP_IF_KN_Hybrid_01_ECUKnockOut_XIX_Infrastructure_Hybrid_01_XIX_network_infrastructure_XIX_BMC_HV: provided-interface=IF_KN_Hybrid_01_ECUKnockOut
      SP_IF_KN_Hybrid_01_ECUKnockOutTimer_XIX_Infrastructure_Hybrid_01_XIX_network_infrastructure_XIX_BMC_HV: provided-interface=IF_KN_Hybrid_01_ECUKnockOutTimer
      SP_IF_NM_aktiv_Konditionierungsbedarf_XIX_Infrastructure_Hybrid_01_XIX_network_infrastructure_XIX_BMC_HV: provided-interface=IF_NM_aktiv_Konditionierungsbedarf
      SP_IF_NM_aktiv_SubbusSteuerung_BMC_HV_XIX_Infrastructure_Hybrid_01_XIX_network_infrastructure_XIX_BMC_HV: provided-interface=IF_NM_aktiv_SubbusSteuerung_BMC_HV
      SP_IF_NM_Hybrid_01_CAB_V12_XIX_Infrastructure_Hybrid_01_XIX_network_infrastructure_XIX_BMC_HV: provided-interface=IF_NM_Hybrid_01_CAB_V12
      SP_IF_NM_Hybrid_01_CBV_AWB_XIX_Infrastructure_Hybrid_01_XIX_network_infrastructure_XIX_BMC_HV: provided-interface=IF_NM_Hybrid_01_CBV_AWB
      SP_IF_NM_Hybrid_01_CBV_CRI_XIX_Infrastructure_Hybrid_01_XIX_network_infrastructure_XIX_BMC_HV: provided-interface=IF_NM_Hybrid_01_CBV_CRI
      SP_IF_NM_Hybrid_01_FCAB_XIX_Infrastructure_Hybrid_01_XIX_network_infrastructure_XIX_BMC_HV: provided-interface=IF_NM_Hybrid_01_FCAB
      SP_IF_NM_Hybrid_01_FCIB_XIX_Infrastructure_Hybrid_01_XIX_network_infrastructure_XIX_BMC_HV: provided-interface=IF_NM_Hybrid_01_FCIB
      SP_IF_NM_Hybrid_01_Lokalaktiv_XIX_Infrastructure_Hybrid_01_XIX_network_infrastructure_XIX_BMC_HV: provided-interface=IF_NM_Hybrid_01_Lokalaktiv
      SP_IF_NM_Hybrid_01_NM_aktiv_Diag_XIX_Infrastructure_Hybrid_01_XIX_network_infrastructure_XIX_BMC_HV: provided-interface=IF_NM_Hybrid_01_NM_aktiv_Diag
      SP_IF_NM_Hybrid_01_NM_aktiv_KL15_XIX_Infrastructure_Hybrid_01_XIX_network_infrastructure_XIX_BMC_HV: provided-interface=IF_NM_Hybrid_01_NM_aktiv_KL15
      SP_IF_NM_Hybrid_01_NM_aktiv_Tmin_XIX_Infrastructure_Hybrid_01_XIX_network_infrastructure_XIX_BMC_HV: provided-interface=IF_NM_Hybrid_01_NM_aktiv_Tmin
      SP_IF_NM_Hybrid_01_NM_State_XIX_Infrastructure_Hybrid_01_XIX_network_infrastructure_XIX_BMC_HV: provided-interface=IF_NM_Hybrid_01_NM_State
      SP_IF_NM_Hybrid_01_SNI_10_XIX_Infrastructure_Hybrid_01_XIX_network_infrastructure_XIX_BMC_HV: provided-interface=IF_NM_Hybrid_01_SNI_10
      SP_IF_NM_Hybrid_01_Subsystemaktiv_XIX_Infrastructure_Hybrid_01_XIX_network_infrastructure_XIX_BMC_HV: provided-interface=IF_NM_Hybrid_01_Subsystemaktiv
      SP_IF_NM_Hybrid_01_UDS_CC_XIX_Infrastructure_Hybrid_01_XIX_network_infrastructure_XIX_BMC_HV: provided-interface=IF_NM_Hybrid_01_UDS_CC
      SP_IF_NM_Hybrid_01_Wakeup_V12_XIX_Infrastructure_Hybrid_01_XIX_network_infrastructure_XIX_BMC_HV: provided-interface=IF_NM_Hybrid_01_Wakeup_V12
    12 x require port:
      RP_IF_DEV_Hybrid_01_Req_00_FD_Data_XIX_Infrastructure_Hybrid_01_XIX_network_infrastructure_XIX_BMC_HV: required-interface=IF_DEV_Hybrid_01_Req_00_FD_Data
      RP_IF_KST_KL_15_XIX_Infrastructure_Hybrid_01_XIX_network_infrastructure_XIX_BMC_HV: required-interface=IF_KST_KL_15
      RP_IF_NM_AWC_FCAB_XIX_Infrastructure_Hybrid_01_XIX_network_infrastructure_XIX_BMC_HV: required-interface=IF_NM_AWC_FCAB
      RP_IF_NM_Dummy01_NM_State_XIX_Infrastructure_Hybrid_01_XIX_network_infrastructure_XIX_BMC_HV: required-interface=IF_NM_Dummy01_NM_State
      RP_IF_NM_Gateway_FCAB_XIX_Infrastructure_Hybrid_01_XIX_network_infrastructure_XIX_BMC_HV: required-interface=IF_NM_Gateway_FCAB
      RP_IF_NM_HVZB_FCAB_XIX_Infrastructure_Hybrid_01_XIX_network_infrastructure_XIX_BMC_HV: required-interface=IF_NM_HVZB_FCAB
      RP_IF_NM_Ladegeraet_FCAB_XIX_Infrastructure_Hybrid_01_XIX_network_infrastructure_XIX_BMC_HV: required-interface=IF_NM_Ladegeraet_FCAB
      RP_IF_NM_SACID_1_FCAB_XIX_Infrastructure_Hybrid_01_XIX_network_infrastructure_XIX_BMC_HV: required-interface=IF_NM_SACID_1_FCAB
      RP_IF_NM_SACID_2_FCAB_XIX_Infrastructure_Hybrid_01_XIX_network_infrastructure_XIX_BMC_HV: required-interface=IF_NM_SACID_2_FCAB
      RP_IF_NVEM_Abschaltstufe_XIX_Infrastructure_Hybrid_01_XIX_network_infrastructure_XIX_BMC_HV: required-interface=IF_NVEM_Abschaltstufe
      RP_IF_SI_NWDF_30_XIX_Infrastructure_Hybrid_01_XIX_network_infrastructure_XIX_BMC_HV: required-interface=IF_SI_NWDF_30
      RP_IF_SI_NWDF_XIX_Infrastructure_Hybrid_01_XIX_network_infrastructure_XIX_BMC_HV: required-interface=IF_SI_NWDF
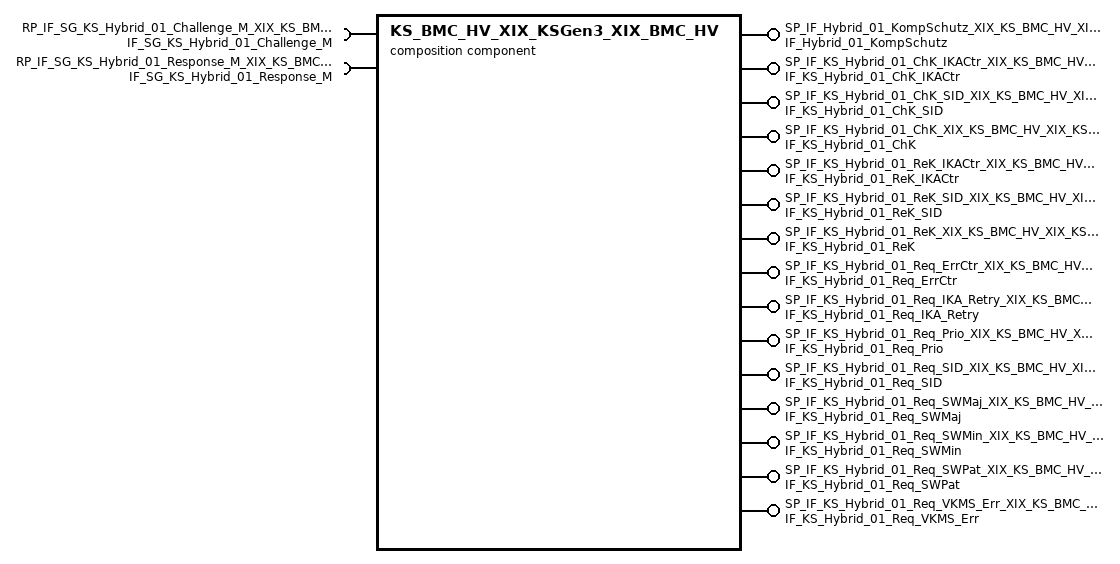
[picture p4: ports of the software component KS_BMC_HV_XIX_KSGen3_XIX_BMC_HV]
  composition sw component type KS_BMC_HV_XIX_KSGen3_XIX_BMC_HV
    15 x provide port:
      SP_IF_Hybrid_01_KompSchutz_XIX_KS_BMC_HV_XIX_KSGen3_XIX_BMC_HV: provided-interface=IF_Hybrid_01_KompSchutz
      SP_IF_KS_Hybrid_01_ChK_IKACtr_XIX_KS_BMC_HV_XIX_KSGen3_XIX_BMC_HV: provided-interface=IF_KS_Hybrid_01_ChK_IKACtr
      SP_IF_KS_Hybrid_01_ChK_SID_XIX_KS_BMC_HV_XIX_KSGen3_XIX_BMC_HV: provided-interface=IF_KS_Hybrid_01_ChK_SID
      SP_IF_KS_Hybrid_01_ChK_XIX_KS_BMC_HV_XIX_KSGen3_XIX_BMC_HV: provided-interface=IF_KS_Hybrid_01_ChK
      SP_IF_KS_Hybrid_01_ReK_IKACtr_XIX_KS_BMC_HV_XIX_KSGen3_XIX_BMC_HV: provided-interface=IF_KS_Hybrid_01_ReK_IKACtr
      SP_IF_KS_Hybrid_01_ReK_SID_XIX_KS_BMC_HV_XIX_KSGen3_XIX_BMC_HV: provided-interface=IF_KS_Hybrid_01_ReK_SID
      SP_IF_KS_Hybrid_01_ReK_XIX_KS_BMC_HV_XIX_KSGen3_XIX_BMC_HV: provided-interface=IF_KS_Hybrid_01_ReK
      SP_IF_KS_Hybrid_01_Req_ErrCtr_XIX_KS_BMC_HV_XIX_KSGen3_XIX_BMC_HV: provided-interface=IF_KS_Hybrid_01_Req_ErrCtr
      SP_IF_KS_Hybrid_01_Req_IKA_Retry_XIX_KS_BMC_HV_XIX_KSGen3_XIX_BMC_HV: provided-interface=IF_KS_Hybrid_01_Req_IKA_Retry
      SP_IF_KS_Hybrid_01_Req_Prio_XIX_KS_BMC_HV_XIX_KSGen3_XIX_BMC_HV: provided-interface=IF_KS_Hybrid_01_Req_Prio
      SP_IF_KS_Hybrid_01_Req_SID_XIX_KS_BMC_HV_XIX_KSGen3_XIX_BMC_HV: provided-interface=IF_KS_Hybrid_01_Req_SID
      SP_IF_KS_Hybrid_01_Req_SWMaj_XIX_KS_BMC_HV_XIX_KSGen3_XIX_BMC_HV: provided-interface=IF_KS_Hybrid_01_Req_SWMaj
      SP_IF_KS_Hybrid_01_Req_SWMin_XIX_KS_BMC_HV_XIX_KSGen3_XIX_BMC_HV: provided-interface=IF_KS_Hybrid_01_Req_SWMin
      SP_IF_KS_Hybrid_01_Req_SWPat_XIX_KS_BMC_HV_XIX_KSGen3_XIX_BMC_HV: provided-interface=IF_KS_Hybrid_01_Req_SWPat
      SP_IF_KS_Hybrid_01_Req_VKMS_Err_XIX_KS_BMC_HV_XIX_KSGen3_XIX_BMC_HV: provided-interface=IF_KS_Hybrid_01_Req_VKMS_Err
    require port RP_IF_SG_KS_Hybrid_01_Challenge_M_XIX_KS_BMC_HV_XIX_KSGen3_XIX_BMC_HV: required-interface=IF_SG_KS_Hybrid_01_Challenge_M
    require port RP_IF_SG_KS_Hybrid_01_Response_M_XIX_KS_BMC_HV_XIX_KSGen3_XIX_BMC_HV: required-interface=IF_SG_KS_Hybrid_01_Response_M
  composition sw component type ORU_Infrastructure_Hybrid_01_XIX_ORU6_XIX_BMC_HV
    require port RP_IF_ORU_Status_XIX_ORU_Infrastructure_Hybrid_01_XIX_ORU6_XIX_BMC_HV: required-interface=IF_ORU_Status
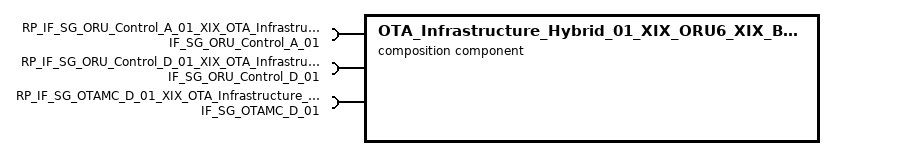
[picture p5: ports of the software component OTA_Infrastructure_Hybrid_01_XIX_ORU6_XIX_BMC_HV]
  composition sw component type OTA_Infrastructure_Hybrid_01_XIX_ORU6_XIX_BMC_HV
    require port RP_IF_SG_ORU_Control_A_01_XIX_OTA_Infrastructure_Hybrid_01_XIX_ORU6_XIX_BMC_HV: required-interface=IF_SG_ORU_Control_A_01
    require port RP_IF_SG_ORU_Control_D_01_XIX_OTA_Infrastructure_Hybrid_01_XIX_ORU6_XIX_BMC_HV: required-interface=IF_SG_ORU_Control_D_01
    require port RP_IF_SG_OTAMC_D_01_XIX_OTA_Infrastructure_Hybrid_01_XIX_ORU6_XIX_BMC_HV: required-interface=IF_SG_OTAMC_D_01
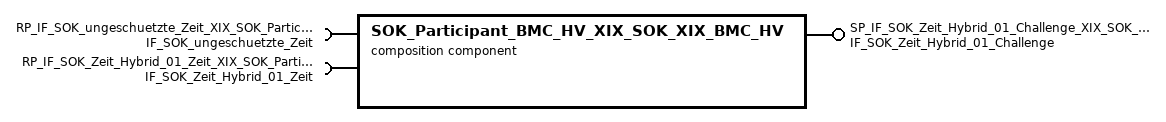
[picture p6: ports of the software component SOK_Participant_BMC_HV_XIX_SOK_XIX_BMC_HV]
  composition sw component type SOK_Participant_BMC_HV_XIX_SOK_XIX_BMC_HV
    provide port SP_IF_SOK_Zeit_Hybrid_01_Challenge_XIX_SOK_Participant_BMC_HV_XIX_SOK_XIX_BMC_HV: provided-interface=IF_SOK_Zeit_Hybrid_01_Challenge
    require port RP_IF_SOK_ungeschuetzte_Zeit_XIX_SOK_Participant_BMC_HV_XIX_SOK_XIX_BMC_HV: required-interface=IF_SOK_ungeschuetzte_Zeit
    require port RP_IF_SOK_Zeit_Hybrid_01_Zeit_XIX_SOK_Participant_BMC_HV_XIX_SOK_XIX_BMC_HV: required-interface=IF_SOK_Zeit_Hybrid_01_Zeit
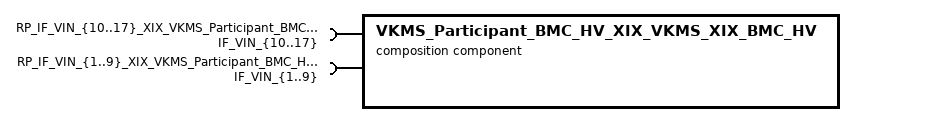
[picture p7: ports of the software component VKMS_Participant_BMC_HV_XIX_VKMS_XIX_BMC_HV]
  composition sw component type VKMS_Participant_BMC_HV_XIX_VKMS_XIX_BMC_HV
    17 x require port:
      RP_IF_VIN_{10..17}_XIX_VKMS_Participant_BMC_HV_XIX_VKMS_XIX_BMC_HV: required-interface=IF_VIN_{10..17}
      RP_IF_VIN_{1..9}_XIX_VKMS_Participant_BMC_HV_XIX_VKMS_XIX_BMC_HV: required-interface=IF_VIN_{1..9}
package /AUTOSAR_PlatformTypes/DataConstraints
  range DataConstr_boolean: raw 0..1
  range DataConstr_sint16: phys -32768..32767, raw -32768..32767
  range DataConstr_sint32: phys -2147483648..2147483647, raw -2147483648..2147483647
  range DataConstr_sint64: phys -9223372036854775808..9223372036854775807, raw -9223372036854775808..9223372036854775807
  range DataConstr_sint8: phys -128..127, raw -128..127
  range DataConstr_uint16: phys 0..65535, raw 0..65535
  range DataConstr_uint32: phys 0..4294967295, raw 0..4294967295
  range DataConstr_uint64: phys 0..18446744073709551615, raw 0..18446744073709551615
  range DataConstr_uint8: phys 0..255, raw 0..255
package /AUTOSAR_PlatformTypes/CompuMethods
  compu method CompuMethod_boolean: 0=false (CompuMethod_boolean_false), 1=true (CompuMethod_boolean_true)
package /RecDataType
  102 x impl type:
    AT_SG_BJB_10: category=STRUCTURE
      6 x element, all with category=TYPE_REFERENCE:
        BJB_10_BZ: implementation-data-type=SG_BJB_10_BJB_10_BZ_type
        BJB_10_CRC: implementation-data-type=SG_BJB_10_BJB_10_CRC_type
        BJB_Lebensdauer_Trennelemente: implementation-data-type=SG_BJB_10_BJB_Lebensdauer_Trennelemente_type
        BJB_Sperrung_Unterspannung: implementation-data-type=SG_BJB_10_BJB_Sperrung_Unterspannung_type
        BJB_Status_HV_Spannungssensorik: implementation-data-type=SG_BJB_10_BJB_Status_HV_Spannungssensorik_type
        BJB_Status_Trennelemente: implementation-data-type=SG_BJB_10_BJB_Status_Trennelemente_type
    SG_BJB_10_BJB_10_BZ_type: implementation-data-type=uint8
    SG_BJB_10_BJB_10_CRC_type: implementation-data-type=uint8
    SG_BJB_10_BJB_Lebensdauer_Trennelemente_type: implementation-data-type=uint32
    SG_BJB_10_BJB_Sperrung_Unterspannung_type: implementation-data-type=uint8
    SG_BJB_10_BJB_Status_HV_Spannungssensorik_type: implementation-data-type=boolean
    SG_BJB_10_BJB_Status_Trennelemente_type: implementation-data-type=uint8
    AT_SG_BJB_11: category=STRUCTURE
      7 x element, all with category=TYPE_REFERENCE:
        BJB_11_BZ: implementation-data-type=SG_BJB_11_BJB_11_BZ_type
        BJB_11_CRC: implementation-data-type=SG_BJB_11_BJB_11_CRC_type
        BJB_Sperrung_Ueberspannung: implementation-data-type=SG_BJB_11_BJB_Sperrung_Ueberspannung_type
        BJB_Ueberspannungszaehler_CMC01: implementation-data-type=SG_BJB_11_BJB_Ueberspannungszaehler_CMC01_type
        BJB_Ueberspannungszaehler_CMC02: implementation-data-type=SG_BJB_11_BJB_Ueberspannungszaehler_CMC02_type
        BJB_Uebertemperaturzaehler_CMC01: implementation-data-type=SG_BJB_11_BJB_Uebertemperaturzaehler_CMC01_type
        BJB_Uebertemperaturzaehler_CMC02: implementation-data-type=SG_BJB_11_BJB_Uebertemperaturzaehler_CMC02_type
    SG_BJB_11_BJB_11_BZ_type: implementation-data-type=uint8
    SG_BJB_11_BJB_11_CRC_type: implementation-data-type=uint8
    SG_BJB_11_BJB_Sperrung_Ueberspannung_type: implementation-data-type=uint8
    SG_BJB_11_BJB_Ueberspannungszaehler_CMC01_type: implementation-data-type=uint16
    SG_BJB_11_BJB_Ueberspannungszaehler_CMC02_type: implementation-data-type=uint16
    SG_BJB_11_BJB_Uebertemperaturzaehler_CMC01_type: implementation-data-type=uint16
    SG_BJB_11_BJB_Uebertemperaturzaehler_CMC02_type: implementation-data-type=uint16
    AT_SG_BJB_12: category=STRUCTURE
      7 x element, all with category=TYPE_REFERENCE:
        BJB_12_BZ: implementation-data-type=SG_BJB_12_BJB_12_BZ_type
        BJB_12_CRC: implementation-data-type=SG_BJB_12_BJB_12_CRC_type
        BJB_Sperrung_Uebertemperatur: implementation-data-type=SG_BJB_12_BJB_Sperrung_Uebertemperatur_type
        BJB_Ueberspannungszaehler_CMC03: implementation-data-type=SG_BJB_12_BJB_Ueberspannungszaehler_CMC03_type
        BJB_Ueberspannungszaehler_CMC04: implementation-data-type=SG_BJB_12_BJB_Ueberspannungszaehler_CMC04_type
        BJB_Uebertemperaturzaehler_CMC03: implementation-data-type=SG_BJB_12_BJB_Uebertemperaturzaehler_CMC03_type
        BJB_Uebertemperaturzaehler_CMC04: implementation-data-type=SG_BJB_12_BJB_Uebertemperaturzaehler_CMC04_type
    SG_BJB_12_BJB_12_BZ_type: implementation-data-type=uint8
    SG_BJB_12_BJB_12_CRC_type: implementation-data-type=uint8
    SG_BJB_12_BJB_Sperrung_Uebertemperatur_type: implementation-data-type=uint8
    SG_BJB_12_BJB_Ueberspannungszaehler_CMC03_type: implementation-data-type=uint16
    SG_BJB_12_BJB_Ueberspannungszaehler_CMC04_type: implementation-data-type=uint16
    SG_BJB_12_BJB_Uebertemperaturzaehler_CMC03_type: implementation-data-type=uint16
    SG_BJB_12_BJB_Uebertemperaturzaehler_CMC04_type: implementation-data-type=uint16
    AT_SG_BJB_13: category=STRUCTURE
      6 x element, all with category=TYPE_REFERENCE:
        BJB_13_BZ: implementation-data-type=SG_BJB_13_BJB_13_BZ_type
        BJB_13_CRC: implementation-data-type=SG_BJB_13_BJB_13_CRC_type
        BJB_Unterspannungszaehler_CMC{01..04}: implementation-data-type=SG_BJB_13_BJB_Unterspannungszaehler_CMC{01..04}_type
    SG_BJB_13_BJB_13_BZ_type: implementation-data-type=uint8
    SG_BJB_13_BJB_13_CRC_type: implementation-data-type=uint8
    SG_BJB_13_BJB_Unterspannungszaehler_CMC{01..04}_type: implementation-data-type=uint16
    AT_SG_HVK_03: category=STRUCTURE
      6 x element, all with category=TYPE_REFERENCE:
        HVK_03_BZ: implementation-data-type=SG_HVK_03_HVK_03_BZ_type
        HVK_03_CRC: implementation-data-type=SG_HVK_03_HVK_03_CRC_type
        HVK_BMC_Sollmodus: implementation-data-type=SG_HVK_03_HVK_BMC_Sollmodus_type
        HVK_BMC_Spannung_Anf: implementation-data-type=SG_HVK_03_HVK_BMC_Spannung_Anf_type
        HVK_Iso_Messung_Start: implementation-data-type=SG_HVK_03_HVK_Iso_Messung_Start_type
        HVK_Istmodus_Anf: implementation-data-type=SG_HVK_03_HVK_Istmodus_Anf_type
    SG_HVK_03_HVK_03_BZ_type: implementation-data-type=uint8
    SG_HVK_03_HVK_03_CRC_type: implementation-data-type=uint8
    SG_HVK_03_HVK_BMC_Sollmodus_type: implementation-data-type=uint8
    SG_HVK_03_HVK_BMC_Spannung_Anf_type: implementation-data-type=uint8
    SG_HVK_03_HVK_Iso_Messung_Start_type: implementation-data-type=uint8
    SG_HVK_03_HVK_Istmodus_Anf_type: implementation-data-type=boolean
    AT_SG_HVLM_14: category=STRUCTURE
      6 x element, all with category=TYPE_REFERENCE:
        HVLM_14_BZ: implementation-data-type=SG_HVLM_14_HVLM_14_BZ_type
        HVLM_14_CRC: implementation-data-type=SG_HVLM_14_HVLM_14_CRC_type
        HVLM_DC_Aufstartmodus: implementation-data-type=SG_HVLM_14_HVLM_DC_Aufstartmodus_type
        HVLM_Start_Pulserkennung: implementation-data-type=SG_HVLM_14_HVLM_Start_Pulserkennung_type
        HVLM_Steckerstatus: implementation-data-type=SG_HVLM_14_HVLM_Steckerstatus_type
        HVLM_ZustandLadeablauf: implementation-data-type=SG_HVLM_14_HVLM_ZustandLadeablauf_type
    SG_HVLM_14_HVLM_14_BZ_type: implementation-data-type=uint8
    SG_HVLM_14_HVLM_14_CRC_type: implementation-data-type=uint8
    SG_HVLM_14_HVLM_DC_Aufstartmodus_type: implementation-data-type=uint8
    SG_HVLM_14_HVLM_Start_Pulserkennung_type: implementation-data-type=boolean
    SG_HVLM_14_HVLM_Steckerstatus_type: implementation-data-type=uint8
    SG_HVLM_14_HVLM_ZustandLadeablauf_type: implementation-data-type=uint8
    AT_SG_KS_Hybrid_01_Challenge_M: category=STRUCTURE
      element KS_Hybrid_01_ChM: implementation-data-type=SG_KS_Hybrid_01_Challenge_M_KS_Hybrid_01_ChM_type
      element KS_Hybrid_01_ChM_IKACtr: implementation-data-type=SG_KS_Hybrid_01_Challenge_M_KS_Hybrid_01_ChM_IKACtr_type
      element KS_Hybrid_01_ChM_SID: implementation-data-type=SG_KS_Hybrid_01_Challenge_M_KS_Hybrid_01_ChM_SID_type
    SG_KS_Hybrid_01_Challenge_M_KS_Hybrid_01_ChM_type: category=ARRAY
      element SG_KS_Hybrid_01_Challenge_M_KS_Hybrid_01_ChM_typeBase: array-size=8, array-size-semantics=FIXED-SIZE, implementation-data-type=uint8
      symbol props SymbolProps: symbol=SG_KS_Hybrid_01_Challenge_M_KS_Hybrid_01_ChM_type
    SG_KS_Hybrid_01_Challenge_M_KS_Hybrid_01_ChM_IKACtr_type: implementation-data-type=uint8
    SG_KS_Hybrid_01_Challenge_M_KS_Hybrid_01_ChM_SID_type: implementation-data-type=uint16
    AT_SG_KS_Hybrid_01_Response_M: category=STRUCTURE
      element KS_Hybrid_01_ReM: implementation-data-type=SG_KS_Hybrid_01_Response_M_KS_Hybrid_01_ReM_type
      element KS_Hybrid_01_ReM_IKACtr: implementation-data-type=SG_KS_Hybrid_01_Response_M_KS_Hybrid_01_ReM_IKACtr_type
      element KS_Hybrid_01_ReM_SID: implementation-data-type=SG_KS_Hybrid_01_Response_M_KS_Hybrid_01_ReM_SID_type
    SG_KS_Hybrid_01_Response_M_KS_Hybrid_01_ReM_type: category=ARRAY
      element SG_KS_Hybrid_01_Response_M_KS_Hybrid_01_ReM_typeBase: array-size=8, array-size-semantics=FIXED-SIZE, implementation-data-type=uint8
      symbol props SymbolProps: symbol=SG_KS_Hybrid_01_Response_M_KS_Hybrid_01_ReM_type
    SG_KS_Hybrid_01_Response_M_KS_Hybrid_01_ReM_IKACtr_type: implementation-data-type=uint8
    SG_KS_Hybrid_01_Response_M_KS_Hybrid_01_ReM_SID_type: implementation-data-type=uint16
    AT_SG_ORU_Control_A_01: category=STRUCTURE
      5 x element, all with category=TYPE_REFERENCE:
        ORU_Control_A_01_BZ: implementation-data-type=SG_ORU_Control_A_01_ORU_Control_A_01_BZ_type
        ORU_Control_A_01_CRC: implementation-data-type=SG_ORU_Control_A_01_ORU_Control_A_01_CRC_type
        OnlineRemoteUpdateControlA: implementation-data-type=SG_ORU_Control_A_01_OnlineRemoteUpdateControlA_type
        OnlineRemoteUpdateControlOldA: implementation-data-type=SG_ORU_Control_A_01_OnlineRemoteUpdateControlOldA_type
        OruControlReleaseA: implementation-data-type=SG_ORU_Control_A_01_OruControlReleaseA_type
    SG_ORU_Control_A_01_ORU_Control_A_01_BZ_type: implementation-data-type=uint8
    SG_ORU_Control_A_01_ORU_Control_A_01_CRC_type: implementation-data-type=uint8
    SG_ORU_Control_A_01_OnlineRemoteUpdateControlA_type: implementation-data-type=uint8
    SG_ORU_Control_A_01_OnlineRemoteUpdateControlOldA_type: implementation-data-type=uint8
    SG_ORU_Control_A_01_OruControlReleaseA_type: implementation-data-type=uint16
    AT_SG_ORU_Control_D_01: category=STRUCTURE
      5 x element, all with category=TYPE_REFERENCE:
        ORU_Control_D_01_BZ: implementation-data-type=SG_ORU_Control_D_01_ORU_Control_D_01_BZ_type
        ORU_Control_D_01_CRC: implementation-data-type=SG_ORU_Control_D_01_ORU_Control_D_01_CRC_type
        OnlineRemoteUpdateControlD: implementation-data-type=SG_ORU_Control_D_01_OnlineRemoteUpdateControlD_type
        OnlineRemoteUpdateControlOldD: implementation-data-type=SG_ORU_Control_D_01_OnlineRemoteUpdateControlOldD_type
        OruControlReleaseD: implementation-data-type=SG_ORU_Control_D_01_OruControlReleaseD_type
    SG_ORU_Control_D_01_ORU_Control_D_01_BZ_type: implementation-data-type=uint8
    SG_ORU_Control_D_01_ORU_Control_D_01_CRC_type: implementation-data-type=uint8
    SG_ORU_Control_D_01_OnlineRemoteUpdateControlD_type: implementation-data-type=uint8
    SG_ORU_Control_D_01_OnlineRemoteUpdateControlOldD_type: implementation-data-type=uint8
    SG_ORU_Control_D_01_OruControlReleaseD_type: implementation-data-type=uint16
    AT_SG_OTAMC_D_01: category=STRUCTURE
      element OTAMC_D_01_BZ: implementation-data-type=SG_OTAMC_D_01_OTAMC_D_01_BZ_type
      element OTAMC_D_01_CRC: implementation-data-type=SG_OTAMC_D_01_OTAMC_D_01_CRC_type
      element VehicleProtectedEnvironment_D: implementation-data-type=SG_OTAMC_D_01_VehicleProtectedEnvironment_D_type
    SG_OTAMC_D_01_OTAMC_D_01_BZ_type: implementation-data-type=uint8
    SG_OTAMC_D_01_OTAMC_D_01_CRC_type: implementation-data-type=uint8
    SG_OTAMC_D_01_VehicleProtectedEnvironment_D_type: implementation-data-type=uint8
    AT_SG_UI1_01: category=STRUCTURE
      4 x element, all with category=TYPE_REFERENCE:
        UI1_KL30_Spannung: implementation-data-type=SG_UI1_01_UI1_KL30_Spannung_type
        UI1_Strom: implementation-data-type=SG_UI1_01_UI1_Strom_type
        UISensorIso_01_BZ: implementation-data-type=SG_UI1_01_UISensorIso_01_BZ_type
        UISensorIso_01_CRC: implementation-data-type=SG_UI1_01_UISensorIso_01_CRC_type
    SG_UI1_01_UI1_KL30_Spannung_type: implementation-data-type=uint8
    SG_UI1_01_UI1_Strom_type: implementation-data-type=uint32
    SG_UI1_01_UISensorIso_01_BZ_type: implementation-data-type=uint8
    SG_UI1_01_UISensorIso_01_CRC_type: implementation-data-type=uint8
    AT_SG_UI1_02: category=STRUCTURE
      7 x element, all with category=TYPE_REFERENCE:
        UI1_Spannung1: implementation-data-type=SG_UI1_02_UI1_Spannung1_type
        UI1_Spannung1_Schalt_Status: implementation-data-type=SG_UI1_02_UI1_Spannung1_Schalt_Status_type
        UI1_Spannung2: implementation-data-type=SG_UI1_02_UI1_Spannung2_type
        UI1_Spannung2_Schalt_Status: implementation-data-type=SG_UI1_02_UI1_Spannung2_Schalt_Status_type
        UI1_Spannung3: implementation-data-type=SG_UI1_02_UI1_Spannung3_type
        UISensorIso_02_BZ: implementation-data-type=SG_UI1_02_UISensorIso_02_BZ_type
        UISensorIso_02_CRC: implementation-data-type=SG_UI1_02_UISensorIso_02_CRC_type
    SG_UI1_02_UI1_Spannung1_type: implementation-data-type=uint16
    SG_UI1_02_UI1_Spannung1_Schalt_Status_type: implementation-data-type=uint8
    SG_UI1_02_UI1_Spannung2_type: implementation-data-type=uint16
    SG_UI1_02_UI1_Spannung2_Schalt_Status_type: implementation-data-type=uint8
    SG_UI1_02_UI1_Spannung3_type: implementation-data-type=uint16
    SG_UI1_02_UISensorIso_02_BZ_type: implementation-data-type=uint8
    SG_UI1_02_UISensorIso_02_CRC_type: implementation-data-type=uint8
    AT_SG_UI2_01: category=STRUCTURE
      4 x element, all with category=TYPE_REFERENCE:
        UI2_KL30_Spannung: implementation-data-type=SG_UI2_01_UI2_KL30_Spannung_type
        UI2_Strom: implementation-data-type=SG_UI2_01_UI2_Strom_type
        UISensorPyro_01_BZ: implementation-data-type=SG_UI2_01_UISensorPyro_01_BZ_type
        UISensorPyro_01_CRC: implementation-data-type=SG_UI2_01_UISensorPyro_01_CRC_type
    SG_UI2_01_UI2_KL30_Spannung_type: implementation-data-type=uint8
    SG_UI2_01_UI2_Strom_type: implementation-data-type=uint32
    SG_UI2_01_UISensorPyro_01_BZ_type: implementation-data-type=uint8
    SG_UI2_01_UISensorPyro_01_CRC_type: implementation-data-type=uint8
    AT_SG_UI2_02: category=STRUCTURE
      7 x element, all with category=TYPE_REFERENCE:
        UI2_Spannung1: implementation-data-type=SG_UI2_02_UI2_Spannung1_type
        UI2_Spannung1_Schalt_Status: implementation-data-type=SG_UI2_02_UI2_Spannung1_Schalt_Status_type
        UI2_Spannung2: implementation-data-type=SG_UI2_02_UI2_Spannung2_type
        UI2_Spannung2_Schalt_Status: implementation-data-type=SG_UI2_02_UI2_Spannung2_Schalt_Status_type
        UI2_Spannung3: implementation-data-type=SG_UI2_02_UI2_Spannung3_type
        UISensorPyro_02_BZ: implementation-data-type=SG_UI2_02_UISensorPyro_02_BZ_type
        UISensorPyro_02_CRC: implementation-data-type=SG_UI2_02_UISensorPyro_02_CRC_type
    SG_UI2_02_UI2_Spannung1_type: implementation-data-type=uint16
    SG_UI2_02_UI2_Spannung1_Schalt_Status_type: implementation-data-type=uint8
    SG_UI2_02_UI2_Spannung2_type: implementation-data-type=uint16
    SG_UI2_02_UI2_Spannung2_Schalt_Status_type: implementation-data-type=uint8
    SG_UI2_02_UI2_Spannung3_type: implementation-data-type=uint16
    SG_UI2_02_UISensorPyro_02_BZ_type: implementation-data-type=uint8
    SG_UI2_02_UISensorPyro_02_CRC_type: implementation-data-type=uint8
    AT_SG_UI2_03: category=STRUCTURE
      7 x element, all with category=TYPE_REFERENCE:
        UI2_HW_Crashleitung_Status: implementation-data-type=SG_UI2_03_UI2_HW_Crashleitung_Status_type
        UI2_Pyro_Status: implementation-data-type=SG_UI2_03_UI2_Pyro_Status_type
        UI2_Spannung{4..6}: implementation-data-type=SG_UI2_03_UI2_Spannung{4..6}_type
        UISensorPyro_03_BZ: implementation-data-type=SG_UI2_03_UISensorPyro_03_BZ_type
        UISensorPyro_03_CRC: implementation-data-type=SG_UI2_03_UISensorPyro_03_CRC_type
    SG_UI2_03_UI2_HW_Crashleitung_Status_type: implementation-data-type=uint8
    SG_UI2_03_UI2_Pyro_Status_type: implementation-data-type=uint8
    SG_UI2_03_UI2_Spannung{4..6}_type: implementation-data-type=uint16
    SG_UI2_03_UISensorPyro_03_BZ_type: implementation-data-type=uint8
    SG_UI2_03_UISensorPyro_03_CRC_type: implementation-data-type=uint8
package /VectorAutosarExplorerGeneratedObjects/PDUS
  pdu Vishnu_Tx_NewPDU: length=8
    signal Vishnu_Tx_NewPDU_NewSignal: start 0, 8 bit, little-endian, system signal Vishnu_Tx_NewPDU_NewSignal_b2a9561a2fc7631b, data-type-policy=OVERRIDE, base-type=uint16
  pdu Vishnu_Test_100Bytes_PDU: length=64
    signal Vishnu_Test_100Bytes_PDU_NewSignal1: start 0, 20 bit, little-endian, system signal Vishnu_Test_100Bytes_PDU_NewSignal1_37542d23452fe910, data-type-policy=OVERRIDE, base-type=BT_AB_Abschaltanf_SIH_BF
    signal Vishnu_Test_100Bytes_PDU_NewSignal2: start 20, 20 bit, little-endian, system signal Vishnu_Test_100Bytes_PDU_NewSignal2_302017e93d94206c, data-type-policy=OVERRIDE, base-type=BT_AB_Abschaltanf_SIH_BF
    signal Vishnu_Test_100Bytes_PDU_NewSignal3: start 40, 20 bit, little-endian, system signal Vishnu_Test_100Bytes_PDU_NewSignal3_ebd34b418955d5b1, data-type-policy=OVERRIDE, base-type=BT_AB_Abschaltanf_SIH_BF
    signal Vishnu_Test_100Bytes_PDU_NewSignal4: start 60, 20 bit, little-endian, system signal Vishnu_Test_100Bytes_PDU_NewSignal4_21c239f862026de9, data-type-policy=OVERRIDE, base-type=BT_AB_Abschaltanf_SIH_BF
  pdu DTC_Test_PDU: length=8
    signal DTC_Test_PDU_Set_Signal: start 0, 8 bit, little-endian, system signal DTC_Test_PDU_Set_Signal_e68158b3301efab7, data-type-policy=OVERRIDE, base-type=BT_AB_Abschaltanf_SIH_BF, to BMC_HV
package /VectorAutosarExplorerGeneratedObjects/I_SIGNALS
  i signal Vishnu_Test_100Bytes_PDU_NewSignal5: data-type-policy=OVERRIDE, length=20, base-type=BT_AB_Abschaltanf_SIH_BF, system-signal=Vishnu_Test_100Bytes_PDU_NewSignal5_2a9e79b5a4a81ebd
package /VectorAutosarExplorerGeneratedObjects/FRAME
  can frame Vishnu_Tx: frame-length=8
    pdu to frame mapping PduToFrameMapping_2f2a0eeaacd55b6e: packing-byte-order=little-endian, pdu=Vishnu_Tx_NewPDU, start-position=0
  can frame Vishnu_Test_100Bytes: frame-length=64
    pdu to frame mapping PduToFrameMapping_02a90956f5ef4e4b: packing-byte-order=little-endian, pdu=Vishnu_Test_100Bytes_PDU, start-position=0
  can frame DTC_Test: frame-length=8
    pdu to frame mapping PduToFrameMapping_78da95e682b0bf29: packing-byte-order=little-endian, pdu=DTC_Test_PDU, start-position=0
package /VectorAutosarExplorerGeneratedObjects/SYSTEM_SIGNALS
  system signal Vishnu_Test_100Bytes_PDU_NewSignal5_2a9e79b5a4a81ebd
package /VectorAutosarExplorerGeneratedObjects/PDU_GROUP
  i signal i pdu group PduGroup_afac5c56b3b64c7983bb0f7ebfc92c5a_Tx: communication-direction=OUT
  i signal i pdu group PduGroup_7d6a32fb6b5340f18c0d3a0826764630_Tx: communication-direction=OUT
  i signal i pdu group PduGroup_bd14174e250b400999f7534078763f9f_Rx: communication-direction=IN
